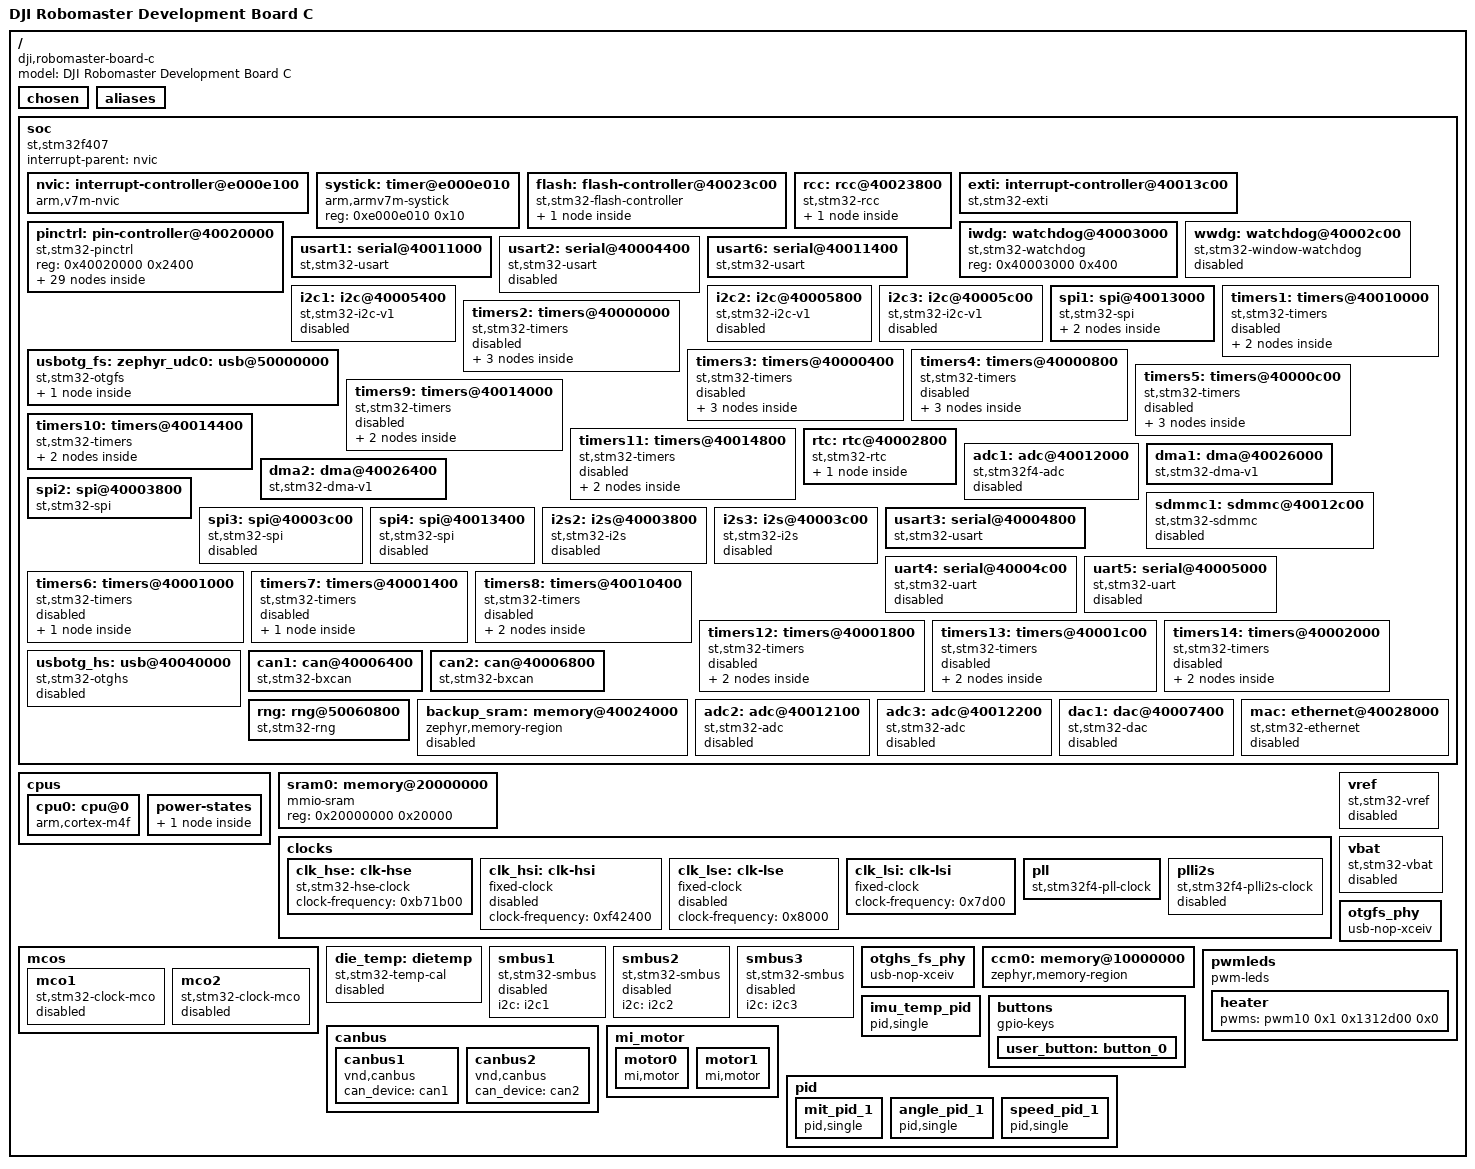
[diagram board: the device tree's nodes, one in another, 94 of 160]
/dts-v1/;

/ {
	#address-cells = < 0x1 >;
	#size-cells = < 0x1 >;
	model = "DJI Robomaster Development Board C";
	compatible = "dji,robomaster-board-c";
	chosen {
		zephyr,flash-controller = &flash;
		zephyr,cortex-m-idle-timer = &rtc;
		zephyr,entropy = &rng;
		zephyr,console = &usart1;
		zephyr,shell-uart = &usart1;
		zephyr,sram = &sram0;
		zephyr,button = &user_button;
		zephyr,flash = &flash0;
		zephyr,canbus = &can1;
		zephyr,ccm = &ccm0;
		ares,pwm = &heater;
		sbus,uart = &usart3;
	};
	aliases {
		vofa = &usart6;
		watchdog0 = &iwdg;
	};
	soc {
		#address-cells = < 0x1 >;
		#size-cells = < 0x1 >;
		compatible = "st,stm32f407", "st,stm32f4", "simple-bus";
		interrupt-parent = < &nvic >;
		ranges;
		nvic: interrupt-controller@e000e100 {
			#address-cells = < 0x1 >;
			compatible = "arm,v7m-nvic";
			reg = < 0xe000e100 0xc00 >;
			interrupt-controller;
			#interrupt-cells = < 0x2 >;
			arm,num-irq-priority-bits = < 0x4 >;
			phandle = < 0x1 >;
		};
		systick: timer@e000e010 {
			compatible = "arm,armv7m-systick";
			reg = < 0xe000e010 0x10 >;
		};
		flash: flash-controller@40023c00 {
			compatible = "st,stm32-flash-controller", "st,stm32f4-flash-controller";
			reg = < 0x40023c00 0x400 >;
			interrupts = < 0x4 0x0 >;
			#address-cells = < 0x1 >;
			#size-cells = < 0x1 >;
			flash0: flash@8000000 {
				compatible = "st,stm32f4-nv-flash", "st,stm32-nv-flash", "soc-nv-flash";
				write-block-size = < 0x1 >;
				max-erase-time = < 0xfa0 >;
				reg = < 0x8000000 0x100000 >;
			};
		};
		rcc: rcc@40023800 {
			compatible = "st,stm32-rcc";
			#clock-cells = < 0x2 >;
			reg = < 0x40023800 0x400 >;
			clocks = < &pll >;
			clock-frequency = < 0xa037a00 >;
			ahb-prescaler = < 0x1 >;
			apb1-prescaler = < 0x4 >;
			apb2-prescaler = < 0x2 >;
			phandle = < 0x3 >;
			rctl: reset-controller {
				compatible = "st,stm32-rcc-rctl";
				#reset-cells = < 0x1 >;
				phandle = < 0x4 >;
			};
		};
		exti: interrupt-controller@40013c00 {
			compatible = "st,stm32-exti";
			interrupt-controller;
			#interrupt-cells = < 0x1 >;
			#address-cells = < 0x1 >;
			reg = < 0x40013c00 0x400 >;
			num-lines = < 0x10 >;
			interrupts = < 0x6 0x0 >, < 0x7 0x0 >, < 0x8 0x0 >, < 0x9 0x0 >, < 0xa 0x0 >, < 0x17 0x0 >, < 0x28 0x0 >;
			interrupt-names = "line0", "line1", "line2", "line3", "line4", "line5-9", "line10-15";
			line-ranges = < 0x0 0x1 >, < 0x1 0x1 >, < 0x2 0x1 >, < 0x3 0x1 >, < 0x4 0x1 >, < 0x5 0x5 >, < 0xa 0x6 >;
		};
		pinctrl: pin-controller@40020000 {
			compatible = "st,stm32-pinctrl";
			#address-cells = < 0x1 >;
			#size-cells = < 0x1 >;
			reg = < 0x40020000 0x2400 >;
			gpioa: gpio@40020000 {
				compatible = "st,stm32-gpio";
				gpio-controller;
				#gpio-cells = < 0x2 >;
				reg = < 0x40020000 0x400 >;
				clocks = < &rcc 0x30 0x1 >;
				phandle = < 0xa >;
			};
			gpiob: gpio@40020400 {
				compatible = "st,stm32-gpio";
				gpio-controller;
				#gpio-cells = < 0x2 >;
				reg = < 0x40020400 0x400 >;
				clocks = < &rcc 0x30 0x2 >;
				phandle = < 0xb >;
			};
			gpioc: gpio@40020800 {
				compatible = "st,stm32-gpio";
				gpio-controller;
				#gpio-cells = < 0x2 >;
				reg = < 0x40020800 0x400 >;
				clocks = < &rcc 0x30 0x4 >;
				phandle = < 0xf >;
			};
			gpiod: gpio@40020c00 {
				compatible = "st,stm32-gpio";
				gpio-controller;
				#gpio-cells = < 0x2 >;
				reg = < 0x40020c00 0x400 >;
				clocks = < &rcc 0x30 0x8 >;
			};
			gpioe: gpio@40021000 {
				compatible = "st,stm32-gpio";
				gpio-controller;
				#gpio-cells = < 0x2 >;
				reg = < 0x40021000 0x400 >;
				clocks = < &rcc 0x30 0x10 >;
			};
			gpiof: gpio@40021400 {
				compatible = "st,stm32-gpio";
				gpio-controller;
				#gpio-cells = < 0x2 >;
				reg = < 0x40021400 0x400 >;
				clocks = < &rcc 0x30 0x20 >;
			};
			gpiog: gpio@40021800 {
				compatible = "st,stm32-gpio";
				gpio-controller;
				#gpio-cells = < 0x2 >;
				reg = < 0x40021800 0x400 >;
				clocks = < &rcc 0x30 0x40 >;
			};
			gpioh: gpio@40021c00 {
				compatible = "st,stm32-gpio";
				gpio-controller;
				#gpio-cells = < 0x2 >;
				reg = < 0x40021c00 0x400 >;
				clocks = < &rcc 0x30 0x80 >;
			};
			gpioi: gpio@40022000 {
				compatible = "st,stm32-gpio";
				gpio-controller;
				#gpio-cells = < 0x2 >;
				reg = < 0x40022000 0x400 >;
				clocks = < &rcc 0x30 0x100 >;
			};
			can1_rx_pd0: can1_rx_pd0 {
				pinmux = < 0x609 >;
				bias-pull-up;
				phandle = < 0x1c >;
			};
			can2_rx_pb5: can2_rx_pb5 {
				pinmux = < 0x2a9 >;
				bias-pull-up;
				phandle = < 0x1e >;
			};
			can1_tx_pd1: can1_tx_pd1 {
				pinmux = < 0x629 >;
				phandle = < 0x1d >;
			};
			can2_tx_pb6: can2_tx_pb6 {
				pinmux = < 0x2c9 >;
				phandle = < 0x1f >;
			};
			spi1_miso_pb4: spi1_miso_pb4 {
				pinmux = < 0x285 >;
				bias-pull-down;
				phandle = < 0xd >;
			};
			spi2_miso_pb14: spi2_miso_pb14 {
				pinmux = < 0x3c5 >;
				bias-pull-down;
				phandle = < 0x15 >;
			};
			spi1_mosi_pa7: spi1_mosi_pa7 {
				pinmux = < 0xe5 >;
				bias-pull-down;
				phandle = < 0xc >;
			};
			spi2_mosi_pb15: spi2_mosi_pb15 {
				pinmux = < 0x3e5 >;
				bias-pull-down;
				phandle = < 0x14 >;
			};
			spi2_nss_pb12: spi2_nss_pb12 {
				pinmux = < 0x385 >;
				bias-pull-up;
				phandle = < 0x17 >;
			};
			spi1_sck_pb3: spi1_sck_pb3 {
				pinmux = < 0x265 >;
				bias-pull-down;
				slew-rate = "very-high-speed";
				phandle = < 0xe >;
			};
			spi2_sck_pb13: spi2_sck_pb13 {
				pinmux = < 0x3a5 >;
				bias-pull-down;
				slew-rate = "very-high-speed";
				phandle = < 0x16 >;
			};
			tim10_ch1_pf6: tim10_ch1_pf6 {
				pinmux = < 0xac3 >;
				phandle = < 0x13 >;
			};
			usart1_rx_pb7: usart1_rx_pb7 {
				pinmux = < 0x2e7 >;
				phandle = < 0x6 >;
			};
			usart3_rx_pc11: usart3_rx_pc11 {
				pinmux = < 0x567 >;
				phandle = < 0x1a >;
			};
			usart6_rx_pg9: usart6_rx_pg9 {
				pinmux = < 0xd28 >;
				phandle = < 0x8 >;
			};
			usart1_tx_pa9: usart1_tx_pa9 {
				pinmux = < 0x127 >;
				bias-pull-up;
				phandle = < 0x5 >;
			};
			usart3_tx_pc10: usart3_tx_pc10 {
				pinmux = < 0x547 >;
				bias-pull-up;
				phandle = < 0x19 >;
			};
			usart6_tx_pg14: usart6_tx_pg14 {
				pinmux = < 0xdc8 >;
				bias-pull-up;
				phandle = < 0x7 >;
			};
			usb_otg_fs_dm_pa11: usb_otg_fs_dm_pa11 {
				pinmux = < 0x16a >;
				phandle = < 0x11 >;
			};
			usb_otg_fs_dp_pa12: usb_otg_fs_dp_pa12 {
				pinmux = < 0x18a >;
				phandle = < 0x12 >;
			};
		};
		iwdg: watchdog@40003000 {
			compatible = "st,stm32-watchdog";
			reg = < 0x40003000 0x400 >;
			status = "okay";
		};
		wwdg: watchdog@40002c00 {
			compatible = "st,stm32-window-watchdog";
			reg = < 0x40002c00 0x400 >;
			clocks = < &rcc 0x40 0x800 >;
			interrupts = < 0x0 0x7 >;
			status = "disabled";
		};
		usart1: serial@40011000 {
			compatible = "st,stm32-usart", "st,stm32-uart";
			reg = < 0x40011000 0x400 >;
			clocks = < &rcc 0x44 0x10 >;
			resets = < &rctl 0x484 >;
			interrupts = < 0x25 0x0 >;
			status = "okay";
			pinctrl-0 = < &usart1_tx_pa9 &usart1_rx_pb7 >;
			pinctrl-names = "default";
			current-speed = < 0x1c200 >;
			data-bits = < 0x8 >;
			stop-bits = "1";
		};
		usart2: serial@40004400 {
			compatible = "st,stm32-usart", "st,stm32-uart";
			reg = < 0x40004400 0x400 >;
			clocks = < &rcc 0x40 0x20000 >;
			resets = < &rctl 0x411 >;
			interrupts = < 0x26 0x0 >;
			status = "disabled";
		};
		usart6: serial@40011400 {
			compatible = "st,stm32-usart", "st,stm32-uart";
			reg = < 0x40011400 0x400 >;
			clocks = < &rcc 0x44 0x20 >;
			resets = < &rctl 0x485 >;
			interrupts = < 0x47 0x0 >;
			status = "okay";
			pinctrl-0 = < &usart6_tx_pg14 &usart6_rx_pg9 >;
			pinctrl-names = "default";
			current-speed = < 0x2625a0 >;
			data-bits = < 0x8 >;
			stop-bits = "1";
			dmas = < &dma2 0x6 0x5 0x440 0x3 >, < &dma2 0x1 0x5 0x480 0x3 >;
			dma-names = "tx", "rx";
		};
		i2c1: i2c@40005400 {
			compatible = "st,stm32-i2c-v1";
			clock-frequency = < 0x186a0 >;
			#address-cells = < 0x1 >;
			#size-cells = < 0x0 >;
			reg = < 0x40005400 0x400 >;
			clocks = < &rcc 0x40 0x200000 >;
			interrupts = < 0x1f 0x0 >, < 0x20 0x0 >;
			interrupt-names = "event", "error";
			status = "disabled";
			phandle = < 0x23 >;
		};
		i2c2: i2c@40005800 {
			compatible = "st,stm32-i2c-v1";
			clock-frequency = < 0x186a0 >;
			#address-cells = < 0x1 >;
			#size-cells = < 0x0 >;
			reg = < 0x40005800 0x400 >;
			clocks = < &rcc 0x40 0x400000 >;
			interrupts = < 0x21 0x0 >, < 0x22 0x0 >;
			interrupt-names = "event", "error";
			status = "disabled";
			phandle = < 0x24 >;
		};
		i2c3: i2c@40005c00 {
			compatible = "st,stm32-i2c-v1";
			clock-frequency = < 0x186a0 >;
			#address-cells = < 0x1 >;
			#size-cells = < 0x0 >;
			reg = < 0x40005c00 0x400 >;
			clocks = < &rcc 0x40 0x800000 >;
			interrupts = < 0x48 0x0 >, < 0x49 0x0 >;
			interrupt-names = "event", "error";
			status = "disabled";
			phandle = < 0x25 >;
		};
		spi1: spi@40013000 {
			compatible = "st,stm32-spi";
			#address-cells = < 0x1 >;
			#size-cells = < 0x0 >;
			reg = < 0x40013000 0x400 >;
			clocks = < &rcc 0x44 0x1000 >;
			interrupts = < 0x23 0x5 >;
			status = "okay";
			cs-gpios = < &gpioa 0x4 0x1 >, < &gpiob 0x0 0x1 >;
			pinctrl-0 = < &spi1_mosi_pa7 &spi1_miso_pb4 &spi1_sck_pb3 >;
			pinctrl-names = "default";
			bmi08x_accel: bmi08x_accel@0 {
				compatible = "bosch,bmi08x-accel";
				status = "okay";
				reg = < 0x0 >;
				spi-max-frequency = < 0x7a1200 >;
				int-gpios = < &gpioc 0x4 0x0 >;
				accel-hz = "800";
				accel-fs = < 0xc >;
				int1-map-io = < 0x1 >;
				int2-map-io = < 0x2 >;
				int1-conf-io = < 0xa >;
				int2-conf-io = < 0xa >;
			};
			bmi08x_gyro: bmi08x_gyro@1 {
				compatible = "bosch,bmi08x-gyro";
				status = "okay";
				reg = < 0x1 >;
				spi-max-frequency = < 0x7a1200 >;
				int-gpios = < &gpioc 0x5 0x0 >;
				gyro-hz = "1000_116";
				gyro-fs = < 0x3e8 >;
				int3-4-map-io = < 0x1 >;
				int3-4-conf-io = < 0x1 >;
			};
		};
		usbotg_fs: zephyr_udc0: usb@50000000 {
			compatible = "st,stm32-otgfs";
			reg = < 0x50000000 0x40000 >;
			interrupts = < 0x43 0x0 >;
			interrupt-names = "otgfs";
			num-bidir-endpoints = < 0x4 >;
			ram-size = < 0x500 >;
			maximum-speed = "full-speed";
			phys = < &otgfs_phy >;
			clocks = < &rcc 0x34 0x80 >, < &rcc 0x7 0xff >;
			status = "okay";
			pinctrl-0 = < &usb_otg_fs_dm_pa11 &usb_otg_fs_dp_pa12 >;
			pinctrl-names = "default";
			cdc_acm_uart0: cdc_acm_uart {
				compatible = "zephyr,cdc-acm-uart";
			};
		};
		timers1: timers@40010000 {
			compatible = "st,stm32-timers";
			reg = < 0x40010000 0x400 >;
			clocks = < &rcc 0x44 0x1 >;
			resets = < &rctl 0x480 >;
			interrupts = < 0x18 0x0 >, < 0x19 0x0 >, < 0x1a 0x0 >, < 0x1b 0x0 >;
			interrupt-names = "brk", "up", "trgcom", "cc";
			st,prescaler = < 0x0 >;
			status = "disabled";
			pwm {
				compatible = "st,stm32-pwm";
				status = "disabled";
				#pwm-cells = < 0x3 >;
			};
			qdec {
				compatible = "st,stm32-qdec";
				status = "disabled";
				st,input-filter-level = < 0x0 >;
			};
		};
		timers2: timers@40000000 {
			compatible = "st,stm32-timers";
			reg = < 0x40000000 0x400 >;
			clocks = < &rcc 0x40 0x1 >;
			resets = < &rctl 0x400 >;
			interrupts = < 0x1c 0x0 >;
			interrupt-names = "global";
			st,prescaler = < 0x0 >;
			status = "disabled";
			pwm {
				compatible = "st,stm32-pwm";
				status = "disabled";
				#pwm-cells = < 0x3 >;
			};
			counter {
				compatible = "st,stm32-counter";
				status = "disabled";
			};
			qdec {
				compatible = "st,stm32-qdec";
				status = "disabled";
				st,input-filter-level = < 0x0 >;
			};
		};
		timers3: timers@40000400 {
			compatible = "st,stm32-timers";
			reg = < 0x40000400 0x400 >;
			clocks = < &rcc 0x40 0x2 >;
			resets = < &rctl 0x401 >;
			interrupts = < 0x1d 0x0 >;
			interrupt-names = "global";
			st,prescaler = < 0x0 >;
			status = "disabled";
			pwm {
				compatible = "st,stm32-pwm";
				status = "disabled";
				#pwm-cells = < 0x3 >;
			};
			counter {
				compatible = "st,stm32-counter";
				status = "disabled";
			};
			qdec {
				compatible = "st,stm32-qdec";
				status = "disabled";
				st,input-filter-level = < 0x0 >;
			};
		};
		timers4: timers@40000800 {
			compatible = "st,stm32-timers";
			reg = < 0x40000800 0x400 >;
			clocks = < &rcc 0x40 0x4 >;
			resets = < &rctl 0x402 >;
			interrupts = < 0x1e 0x0 >;
			interrupt-names = "global";
			st,prescaler = < 0x0 >;
			status = "disabled";
			pwm {
				compatible = "st,stm32-pwm";
				status = "disabled";
				#pwm-cells = < 0x3 >;
			};
			counter {
				compatible = "st,stm32-counter";
				status = "disabled";
			};
			qdec {
				compatible = "st,stm32-qdec";
				status = "disabled";
				st,input-filter-level = < 0x0 >;
			};
		};
		timers5: timers@40000c00 {
			compatible = "st,stm32-timers";
			reg = < 0x40000c00 0x400 >;
			clocks = < &rcc 0x40 0x8 >;
			resets = < &rctl 0x403 >;
			interrupts = < 0x32 0x0 >;
			interrupt-names = "global";
			st,prescaler = < 0x0 >;
			status = "disabled";
			pwm {
				compatible = "st,stm32-pwm";
				status = "disabled";
				#pwm-cells = < 0x3 >;
			};
			counter {
				compatible = "st,stm32-counter";
				status = "disabled";
			};
			qdec {
				compatible = "st,stm32-qdec";
				status = "disabled";
				st,input-filter-level = < 0x0 >;
			};
		};
		timers9: timers@40014000 {
			compatible = "st,stm32-timers";
			reg = < 0x40014000 0x400 >;
			clocks = < &rcc 0x44 0x10000 >;
			resets = < &rctl 0x490 >;
			interrupts = < 0x18 0x0 >;
			interrupt-names = "global";
			st,prescaler = < 0x0 >;
			status = "disabled";
			pwm {
				compatible = "st,stm32-pwm";
				status = "disabled";
				#pwm-cells = < 0x3 >;
			};
			counter {
				compatible = "st,stm32-counter";
				status = "disabled";
			};
		};
		timers10: timers@40014400 {
			compatible = "st,stm32-timers";
			reg = < 0x40014400 0x400 >;
			clocks = < &rcc 0x44 0x20000 >;
			resets = < &rctl 0x491 >;
			interrupts = < 0x19 0x0 >;
			interrupt-names = "global";
			st,prescaler = < 0x2710 >;
			status = "okay";
			pwm10: pwm {
				compatible = "st,stm32-pwm";
				status = "okay";
				#pwm-cells = < 0x3 >;
				pinctrl-0 = < &tim10_ch1_pf6 >;
				pinctrl-names = "default";
				phandle = < 0x26 >;
			};
			counter {
				compatible = "st,stm32-counter";
				status = "disabled";
			};
		};
		timers11: timers@40014800 {
			compatible = "st,stm32-timers";
			reg = < 0x40014800 0x400 >;
			clocks = < &rcc 0x44 0x40000 >;
			resets = < &rctl 0x492 >;
			interrupts = < 0x1a 0x0 >;
			interrupt-names = "global";
			st,prescaler = < 0x0 >;
			status = "disabled";
			pwm {
				compatible = "st,stm32-pwm";
				status = "disabled";
				#pwm-cells = < 0x3 >;
			};
			counter {
				compatible = "st,stm32-counter";
				status = "disabled";
			};
		};
		rtc: rtc@40002800 {
			compatible = "st,stm32-rtc";
			reg = < 0x40002800 0x400 >;
			interrupts = < 0x29 0x0 >;
			clocks = < &rcc 0x40 0x10000000 >, < &rcc 0x3 0x10c80070 >;
			prescaler = < 0x8000 >;
			alarms-count = < 0x2 >;
			alrm-exti-line = < 0x11 >;
			status = "okay";
			bbram: backup_regs {
				compatible = "st,stm32-bbram";
				st,backup-regs = < 0x14 >;
				status = "disabled";
			};
		};
		adc1: adc@40012000 {
			compatible = "st,stm32f4-adc", "st,stm32-adc";
			reg = < 0x40012000 0x400 >;
			clocks = < &rcc 0x44 0x100 >;
			interrupts = < 0x12 0x0 >;
			status = "disabled";
			#io-channel-cells = < 0x1 >;
			resolutions = < 0x607804 0x517804 0x427804 0x337804 >;
			sampling-times = < 0x3 0xf 0x1c 0x38 0x54 0x70 0x90 0x1e0 >;
			st,adc-clock-source = "SYNC";
			st,adc-sequencer = "FULLY_CONFIGURABLE";
			st,adc-oversampler = "OVERSAMPLER_NONE";
			phandle = < 0x22 >;
		};
		dma1: dma@40026000 {
			compatible = "st,stm32-dma-v1";
			#dma-cells = < 0x4 >;
			reg = < 0x40026000 0x400 >;
			interrupts = < 0xb 0x0 0xc 0x0 0xd 0x0 0xe 0x0 0xf 0x0 0x10 0x0 0x11 0x0 0x2f 0x0 >;
			clocks = < &rcc 0x30 0x200000 >;
			status = "okay";
			phandle = < 0x18 >;
		};
		dma2: dma@40026400 {
			compatible = "st,stm32-dma-v1";
			#dma-cells = < 0x4 >;
			reg = < 0x40026400 0x400 >;
			interrupts = < 0x38 0x0 0x39 0x0 0x3a 0x0 0x3b 0x0 0x3c 0x0 0x44 0x0 0x45 0x0 0x46 0x0 >;
			clocks = < &rcc 0x30 0x400000 >;
			st,mem2mem;
			status = "okay";
			phandle = < 0x9 >;
		};
		sdmmc1: sdmmc@40012c00 {
			compatible = "st,stm32-sdmmc";
			reg = < 0x40012c00 0x400 >;
			clocks = < &rcc 0x44 0x800 >, < &rcc 0x7 0xff >;
			resets = < &rctl 0x48b >;
			interrupts = < 0x31 0x0 >;
			status = "disabled";
		};
		spi2: spi@40003800 {
			compatible = "st,stm32-spi";
			#address-cells = < 0x1 >;
			#size-cells = < 0x0 >;
			reg = < 0x40003800 0x400 >;
			clocks = < &rcc 0x40 0x4000 >;
			interrupts = < 0x24 0x5 >;
			status = "okay";
			pinctrl-0 = < &spi2_mosi_pb15 &spi2_miso_pb14 &spi2_sck_pb13 &spi2_nss_pb12 >;
			pinctrl-names = "default";
			dmas = < &dma1 0x3 0x0 0x480 0x3 >, < &dma1 0x4 0x0 0x440 0x3 >;
			dma-names = "rx", "tx";
		};
		spi3: spi@40003c00 {
			compatible = "st,stm32-spi";
			#address-cells = < 0x1 >;
			#size-cells = < 0x0 >;
			reg = < 0x40003c00 0x400 >;
			clocks = < &rcc 0x40 0x8000 >;
			interrupts = < 0x33 0x5 >;
			status = "disabled";
		};
		spi4: spi@40013400 {
			compatible = "st,stm32-spi";
			#address-cells = < 0x1 >;
			#size-cells = < 0x0 >;
			reg = < 0x40013400 0x400 >;
			clocks = < &rcc 0x44 0x2000 >;
			interrupts = < 0x54 0x5 >;
			status = "disabled";
		};
		i2s2: i2s@40003800 {
			compatible = "st,stm32-i2s";
			#address-cells = < 0x1 >;
			#size-cells = < 0x0 >;
			reg = < 0x40003800 0x400 >;
			clocks = < &rcc 0x40 0x4000 >;
			interrupts = < 0x24 0x5 >;
			dmas = < &dma1 0x4 0x0 0x400 0x3 &dma1 0x3 0x0 0x400 0x3 >;
			dma-names = "tx", "rx";
			status = "disabled";
		};
		i2s3: i2s@40003c00 {
			compatible = "st,stm32-i2s";
			#address-cells = < 0x1 >;
			#size-cells = < 0x0 >;
			reg = < 0x40003c00 0x400 >;
			clocks = < &rcc 0x40 0x8000 >;
			interrupts = < 0x33 0x5 >;
			dmas = < &dma1 0x5 0x0 0x400 0x3 &dma1 0x0 0x0 0x400 0x3 >;
			dma-names = "tx", "rx";
			status = "disabled";
		};
		usart3: serial@40004800 {
			compatible = "st,stm32-usart", "st,stm32-uart";
			reg = < 0x40004800 0x400 >;
			clocks = < &rcc 0x40 0x40000 >;
			resets = < &rctl 0x412 >;
			interrupts = < 0x27 0x0 >;
			status = "okay";
			pinctrl-0 = < &usart3_tx_pc10 &usart3_rx_pc11 >;
			pinctrl-names = "default";
			current-speed = < 0x186a0 >;
			data-bits = < 0x8 >;
			stop-bits = "2";
			parity = "even";
			dmas = < &dma1 0x1 0x4 0x480 0x3 >, < &dma1 0x3 0x4 0x440 0x3 >;
			dma-names = "rx", "tx";
		};
		uart4: serial@40004c00 {
			compatible = "st,stm32-uart";
			reg = < 0x40004c00 0x400 >;
			clocks = < &rcc 0x40 0x80000 >;
			resets = < &rctl 0x413 >;
			interrupts = < 0x34 0x0 >;
			status = "disabled";
		};
		uart5: serial@40005000 {
			compatible = "st,stm32-uart";
			reg = < 0x40005000 0x400 >;
			clocks = < &rcc 0x40 0x100000 >;
			resets = < &rctl 0x414 >;
			interrupts = < 0x35 0x0 >;
			status = "disabled";
		};
		timers6: timers@40001000 {
			compatible = "st,stm32-timers";
			reg = < 0x40001000 0x400 >;
			clocks = < &rcc 0x40 0x10 >;
			resets = < &rctl 0x404 >;
			interrupts = < 0x36 0x0 >;
			interrupt-names = "global";
			st,prescaler = < 0x0 >;
			status = "disabled";
			counter {
				compatible = "st,stm32-counter";
				status = "disabled";
			};
		};
		timers7: timers@40001400 {
			compatible = "st,stm32-timers";
			reg = < 0x40001400 0x400 >;
			clocks = < &rcc 0x40 0x20 >;
			resets = < &rctl 0x405 >;
			interrupts = < 0x37 0x0 >;
			interrupt-names = "global";
			st,prescaler = < 0x0 >;
			status = "disabled";
			counter {
				compatible = "st,stm32-counter";
				status = "disabled";
			};
		};
		timers8: timers@40010400 {
			compatible = "st,stm32-timers";
			reg = < 0x40010400 0x400 >;
			clocks = < &rcc 0x44 0x2 >;
			resets = < &rctl 0x481 >;
			interrupts = < 0x2b 0x0 >, < 0x2c 0x0 >, < 0x2d 0x0 >, < 0x2e 0x0 >;
			interrupt-names = "brk", "up", "trgcom", "cc";
			st,prescaler = < 0x0 >;
			status = "disabled";
			pwm {
				compatible = "st,stm32-pwm";
				status = "disabled";
				#pwm-cells = < 0x3 >;
			};
			qdec {
				compatible = "st,stm32-qdec";
				status = "disabled";
				st,input-filter-level = < 0x0 >;
			};
		};
		timers12: timers@40001800 {
			compatible = "st,stm32-timers";
			reg = < 0x40001800 0x400 >;
			clocks = < &rcc 0x40 0x40 >;
			resets = < &rctl 0x406 >;
			interrupts = < 0x2b 0x0 >;
			interrupt-names = "global";
			st,prescaler = < 0x0 >;
			status = "disabled";
			pwm {
				compatible = "st,stm32-pwm";
				status = "disabled";
				#pwm-cells = < 0x3 >;
			};
			counter {
				compatible = "st,stm32-counter";
				status = "disabled";
			};
		};
		timers13: timers@40001c00 {
			compatible = "st,stm32-timers";
			reg = < 0x40001c00 0x400 >;
			clocks = < &rcc 0x40 0x80 >;
			resets = < &rctl 0x407 >;
			interrupts = < 0x2c 0x0 >;
			interrupt-names = "global";
			st,prescaler = < 0x0 >;
			status = "disabled";
			pwm {
				compatible = "st,stm32-pwm";
				status = "disabled";
				#pwm-cells = < 0x3 >;
			};
			counter {
				compatible = "st,stm32-counter";
				status = "disabled";
			};
		};
		timers14: timers@40002000 {
			compatible = "st,stm32-timers";
			reg = < 0x40002000 0x400 >;
			clocks = < &rcc 0x40 0x100 >;
			resets = < &rctl 0x408 >;
			interrupts = < 0x2d 0x0 >;
			interrupt-names = "global";
			st,prescaler = < 0x0 >;
			status = "disabled";
			pwm {
				compatible = "st,stm32-pwm";
				status = "disabled";
				#pwm-cells = < 0x3 >;
			};
			counter {
				compatible = "st,stm32-counter";
				status = "disabled";
			};
		};
		usbotg_hs: usb@40040000 {
			compatible = "st,stm32-otghs";
			reg = < 0x40040000 0x40000 >;
			interrupts = < 0x4d 0x0 >, < 0x4a 0x0 >, < 0x4b 0x0 >;
			interrupt-names = "otghs", "ep1_out", "ep1_in";
			num-bidir-endpoints = < 0x6 >;
			ram-size = < 0x1000 >;
			maximum-speed = "full-speed";
			phys = < &otghs_fs_phy >;
			clocks = < &rcc 0x30 0x20000000 >, < &rcc 0x7 0xff >;
			status = "disabled";
		};
		can1: can@40006400 {
			compatible = "st,stm32-bxcan";
			reg = < 0x40006400 0x400 >;
			interrupts = < 0x13 0x0 >, < 0x14 0x0 >, < 0x15 0x0 >, < 0x16 0x0 >;
			interrupt-names = "TX", "RX0", "RX1", "SCE";
			clocks = < &rcc 0x40 0x2000000 >;
			status = "okay";
			pinctrl-0 = < &can1_rx_pd0 &can1_tx_pd1 >;
			pinctrl-names = "default";
			bitrate = < 0xf4240 >;
			phandle = < 0x27 >;
		};
		can2: can@40006800 {
			compatible = "st,stm32-bxcan";
			reg = < 0x40006800 0x400 >;
			interrupts = < 0x3f 0x0 >, < 0x40 0x0 >, < 0x41 0x0 >, < 0x42 0x0 >;
			interrupt-names = "TX", "RX0", "RX1", "SCE";
			clocks = < &rcc 0x40 0x6000000 >;
			master-can-reg = < 0x40006400 >;
			status = "okay";
			pinctrl-0 = < &can2_rx_pb5 &can2_tx_pb6 >;
			pinctrl-names = "default";
			bitrate = < 0xf4240 >;
			phandle = < 0x28 >;
		};
		rng: rng@50060800 {
			compatible = "st,stm32-rng";
			reg = < 0x50060800 0x400 >;
			interrupts = < 0x50 0x0 >;
			clocks = < &rcc 0x34 0x40 >;
			status = "okay";
		};
		backup_sram: memory@40024000 {
			compatible = "zephyr,memory-region", "st,stm32-backup-sram";
			reg = < 0x40024000 0x1000 >;
			clocks = < &rcc 0x30 0x40000 >;
			zephyr,memory-region = "BACKUP_SRAM";
			status = "disabled";
		};
		adc2: adc@40012100 {
			compatible = "st,stm32-adc";
			reg = < 0x40012100 0x50 >;
			clocks = < &rcc 0x44 0x200 >;
			interrupts = < 0x12 0x0 >;
			status = "disabled";
			#io-channel-cells = < 0x1 >;
			resolutions = < 0x607804 0x517804 0x427804 0x337804 >;
			sampling-times = < 0x3 0xf 0x1c 0x38 0x54 0x70 0x90 0x1e0 >;
			st,adc-clock-source = "SYNC";
			st,adc-sequencer = "FULLY_CONFIGURABLE";
			st,adc-oversampler = "OVERSAMPLER_NONE";
		};
		adc3: adc@40012200 {
			compatible = "st,stm32-adc";
			reg = < 0x40012200 0x50 >;
			clocks = < &rcc 0x44 0x400 >;
			interrupts = < 0x12 0x0 >;
			status = "disabled";
			#io-channel-cells = < 0x1 >;
			resolutions = < 0x607804 0x517804 0x427804 0x337804 >;
			sampling-times = < 0x3 0xf 0x1c 0x38 0x54 0x70 0x90 0x1e0 >;
			st,adc-clock-source = "SYNC";
			st,adc-sequencer = "FULLY_CONFIGURABLE";
			st,adc-oversampler = "OVERSAMPLER_NONE";
		};
		dac1: dac@40007400 {
			compatible = "st,stm32-dac";
			reg = < 0x40007400 0x400 >;
			clocks = < &rcc 0x40 0x20000000 >;
			status = "disabled";
			#io-channel-cells = < 0x1 >;
		};
		mac: ethernet@40028000 {
			compatible = "st,stm32-ethernet";
			reg = < 0x40028000 0x8000 >;
			interrupts = < 0x3d 0x0 >;
			clock-names = "stmmaceth", "mac-clk-tx", "mac-clk-rx", "mac-clk-ptp";
			clocks = < &rcc 0x30 0x2000000 >, < &rcc 0x30 0x4000000 >, < &rcc 0x30 0x8000000 >, < &rcc 0x30 0x10000000 >;
			status = "disabled";
		};
	};
	cpus {
		#address-cells = < 0x1 >;
		#size-cells = < 0x0 >;
		cpu0: cpu@0 {
			device_type = "cpu";
			compatible = "arm,cortex-m4f";
			reg = < 0x0 >;
			cpu-power-states = < &stop >;
		};
		power-states {
			stop: stop {
				compatible = "zephyr,power-state";
				power-state-name = "suspend-to-idle";
				min-residency-us = < 0x190 >;
				exit-latency-us = < 0x12c >;
				phandle = < 0x20 >;
			};
		};
	};
	sram0: memory@20000000 {
		compatible = "mmio-sram";
		reg = < 0x20000000 0x20000 >;
	};
	clocks {
		clk_hse: clk-hse {
			#clock-cells = < 0x0 >;
			compatible = "st,stm32-hse-clock";
			status = "okay";
			clock-frequency = < 0xb71b00 >;
			phandle = < 0x21 >;
		};
		clk_hsi: clk-hsi {
			#clock-cells = < 0x0 >;
			compatible = "fixed-clock";
			clock-frequency = < 0xf42400 >;
			status = "disabled";
		};
		clk_lse: clk-lse {
			#clock-cells = < 0x0 >;
			compatible = "fixed-clock";
			clock-frequency = < 0x8000 >;
			status = "disabled";
		};
		clk_lsi: clk-lsi {
			#clock-cells = < 0x0 >;
			compatible = "fixed-clock";
			clock-frequency = < 0x7d00 >;
			status = "okay";
		};
		pll: pll {
			#clock-cells = < 0x0 >;
			compatible = "st,stm32f4-pll-clock";
			status = "okay";
			div-m = < 0x6 >;
			mul-n = < 0xa8 >;
			div-p = < 0x2 >;
			div-q = < 0x4 >;
			clocks = < &clk_hse >;
			phandle = < 0x2 >;
		};
		plli2s: plli2s {
			#clock-cells = < 0x0 >;
			compatible = "st,stm32f4-plli2s-clock";
			status = "disabled";
		};
	};
	mcos {
		mco1: mco1 {
			compatible = "st,stm32-clock-mco";
			status = "disabled";
		};
		mco2: mco2 {
			compatible = "st,stm32-clock-mco";
			status = "disabled";
		};
	};
	die_temp: dietemp {
		compatible = "st,stm32-temp-cal";
		ts-cal1-addr = < 0x1fff7a2c >;
		ts-cal2-addr = < 0x1fff7a2e >;
		ts-cal1-temp = < 0x1e >;
		ts-cal2-temp = < 0x6e >;
		ts-cal-vrefanalog = < 0xce4 >;
		io-channels = < &adc1 0x10 >;
		status = "disabled";
	};
	vref: vref {
		compatible = "st,stm32-vref";
		vrefint-cal-addr = < 0x1fff7a2a >;
		vrefint-cal-mv = < 0xce4 >;
		io-channels = < &adc1 0x11 >;
		status = "disabled";
	};
	vbat: vbat {
		compatible = "st,stm32-vbat";
		ratio = < 0x4 >;
		io-channels = < &adc1 0x12 >;
		status = "disabled";
	};
	otgfs_phy: otgfs_phy {
		compatible = "usb-nop-xceiv";
		#phy-cells = < 0x0 >;
		phandle = < 0x10 >;
	};
	smbus1: smbus1 {
		compatible = "st,stm32-smbus";
		#address-cells = < 0x1 >;
		#size-cells = < 0x0 >;
		i2c = < &i2c1 >;
		status = "disabled";
	};
	smbus2: smbus2 {
		compatible = "st,stm32-smbus";
		#address-cells = < 0x1 >;
		#size-cells = < 0x0 >;
		i2c = < &i2c2 >;
		status = "disabled";
	};
	smbus3: smbus3 {
		compatible = "st,stm32-smbus";
		#address-cells = < 0x1 >;
		#size-cells = < 0x0 >;
		i2c = < &i2c3 >;
		status = "disabled";
	};
	otghs_fs_phy: otghs_fs_phy {
		compatible = "usb-nop-xceiv";
		#phy-cells = < 0x0 >;
		phandle = < 0x1b >;
	};
	ccm0: memory@10000000 {
		compatible = "zephyr,memory-region", "st,stm32-ccm";
		reg = < 0x10000000 0x10000 >;
		zephyr,memory-region = "CCM";
	};
	pwmleds: pwmleds {
		compatible = "pwm-leds";
		status = "okay";
		heater: heater {
			pwms = < &pwm10 0x1 0x1312d00 0x0 >;
		};
	};
	imu_temp_pid: imu_temp_pid {
		#controller-cells = < 0x0 >;
		compatible = "pid,single";
		k_p = "6000000";
		k_d = "0.02";
		out_max = "20000000.000000";
		offset = "6750000.000000";
	};
	buttons {
		compatible = "gpio-keys";
		user_button: button_0 {
			gpios = < &gpioa 0x0 0x11 >;
			label = "User Button";
			zephyr,code = < 0xb >;
		};
	};
	canbus {
		canbus1: canbus1 {
			compatible = "vnd,canbus";
			status = "okay";
			can_device = < &can1 >;
			phandle = < 0x29 >;
		};
		canbus2: canbus2 {
			compatible = "vnd,canbus";
			status = "okay";
			can_device = < &can2 >;
		};
	};
	mi_motor {
		motor0: motor0 {
			compatible = "mi,motor";
			id = < 0x1 >;
			rx_id = < 0x1 >;
			tx_id = < 0x1 >;
			gear_ratio = "7.75";
			status = "okay";
			can_channel = < &canbus1 >;
			controllers = < &mit_pid_1 &angle_pid_1 &speed_pid_1 >;
			capabilities = "mit", "pv", "vo";
		};
		motor1: motor1 {
			compatible = "mi,motor";
			id = < 0x2 >;
			rx_id = < 0x2 >;
			tx_id = < 0x2 >;
			gear_ratio = "7.75";
			status = "okay";
			can_channel = < &canbus1 >;
			controllers = < &mit_pid_1 &angle_pid_1 &speed_pid_1 >;
			capabilities = "mit", "pv", "vo";
		};
	};
	pid {
		mit_pid_1: mit_pid_1 {
			#controller-cells = < 0x0 >;
			compatible = "pid,single";
			k_p = "30";
			k_i = "0.0";
			k_d = "3.5";
			phandle = < 0x2a >;
		};
		angle_pid_1: angle_pid_1 {
			#controller-cells = < 0x0 >;
			compatible = "pid,single";
			k_p = "10";
			k_i = "0.0";
			k_d = "0.8";
			phandle = < 0x2b >;
		};
		speed_pid_1: speed_pid_1 {
			#controller-cells = < 0x0 >;
			compatible = "pid,single";
			k_p = "10";
			k_i = "0.0";
			k_d = "0.8";
			phandle = < 0x2c >;
		};
	};
};
